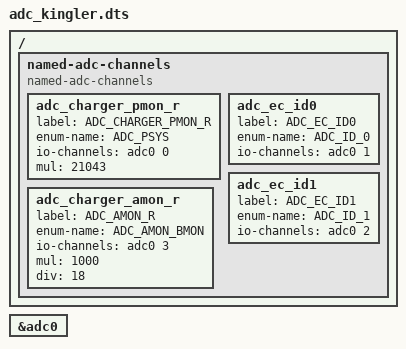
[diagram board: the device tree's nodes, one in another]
/* Copyright 2022 The Chromium OS Authors. All rights reserved.
 * Use of this source code is governed by a BSD-style license that can be
 * found in the LICENSE file.
 */

/ {
	named-adc-channels {
		compatible = "named-adc-channels";

		adc_charger_pmon_r {
			label = "ADC_CHARGER_PMON_R";
			enum-name = "ADC_PSYS";
			io-channels = <&adc0 0>;
			/*
			 * ISL9238C PSYS output is 1.44 uA/W over 33K resistor.
			 */
			mul = <21043>;
		};
		adc_ec_id0 {
			label = "ADC_EC_ID0";
			enum-name = "ADC_ID_0";
			io-channels = <&adc0 1>;
		};
		adc_ec_id1 {
			label = "ADC_EC_ID1";
			enum-name = "ADC_ID_1";
			io-channels = <&adc0 2>;
		};
		adc_charger_amon_r {
			label = "ADC_AMON_R";
			enum-name = "ADC_AMON_BMON";
			io-channels = <&adc0 3>;
			mul = <1000>;
			div = <18>;
		};
	};
};

&adc0 {
	status = "okay";
};
